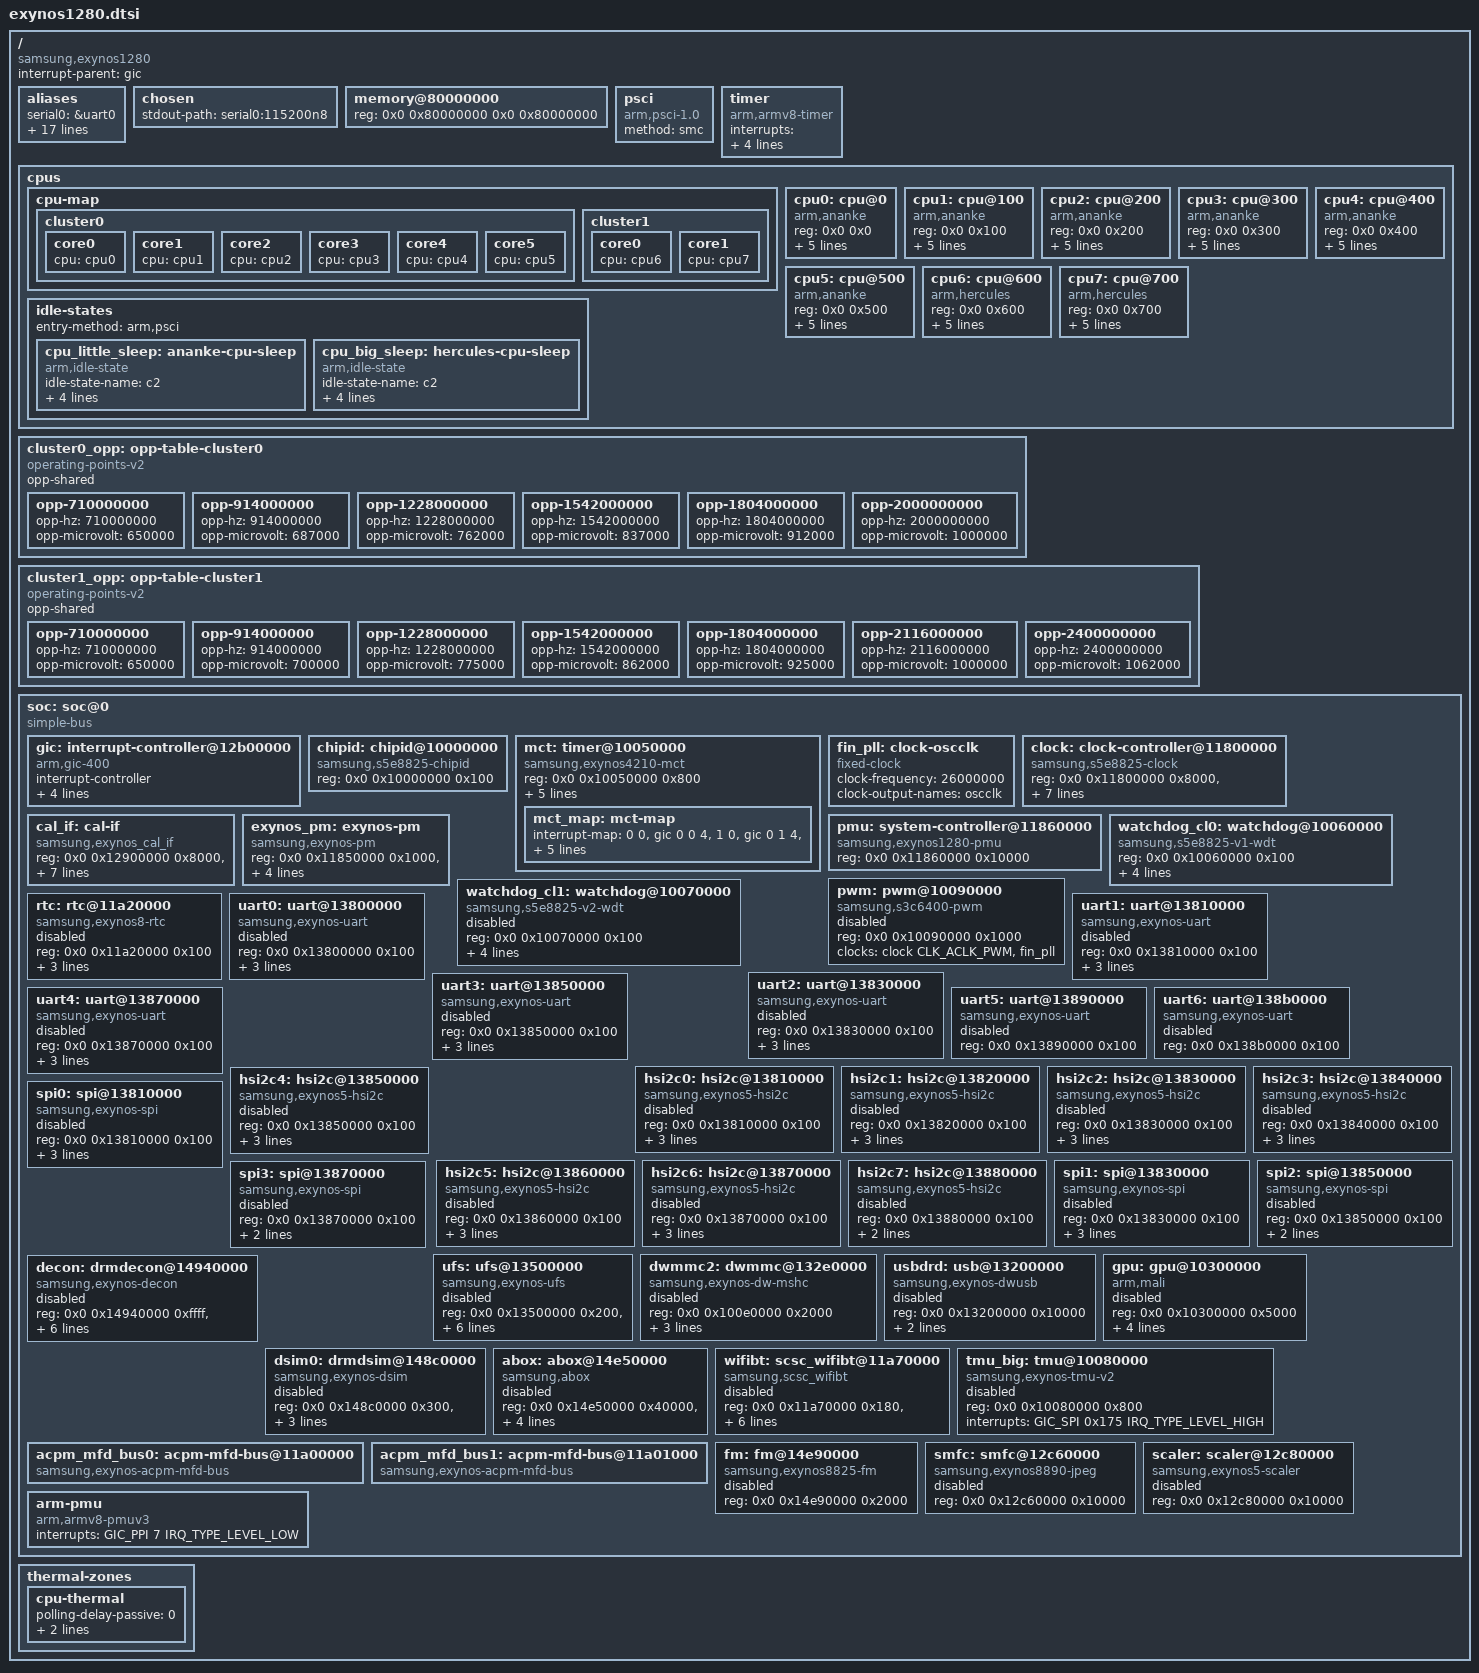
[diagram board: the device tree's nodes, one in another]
// SPDX-License-Identifier: GPL-2.0
/*
 * Samsung Exynos 1280 (s5e8825) SoC Device Tree Source
 *
 * Base addresses, IRQ numbers, and compatible strings are transcribed from
 * the device tree shipped in Samsung's official firmware
 * (A536BXXSMGZE1, SM-A536B / Galaxy A53 5G), extracted from vendor_boot.img.
 * See docs/reference-a53-real.dts for the full decoded dump.
 *
 * Key facts learned from the real DT:
 *   - Interrupt controller is arm,gic-400 (GICv2), NOT GICv3.
 *   - The clock tree is driven through ACPM IPC (acpm-ipc-channel) rather
 *     than direct register writes; the samsung,s5e8825-clock node is the
 *     ACPM front-end, and samsung,exynos_cal_if is the CAL-IF register map.
 *   - CPUs are arm,ananke (Cortex-A55, 6 cores, LITTLE) and arm,hercules
 *     (Cortex-A78, 2 cores, big). cluster0 = LITTLE, cluster1 = big.
 *   - 26 MHz oscillator (0x018cba80).
 *
 * Board-specific GPIO/regulator details remain in per-device .dts files.
 */

#include <dt-bindings/clock/samsung,exynos1280-clk.h>
#include <dt-bindings/interrupt-controller/arm-gic.h>
#include <dt-bindings/gpio/gpio.h>

/ {
	compatible = "samsung,exynos1280";
	#address-cells = <2>;
	#size-cells = <2>;

	interrupt-parent = <&gic>;

	aliases {
		serial0 = &uart0;
		serial1 = &uart1;
		serial2 = &uart2;
		serial3 = &uart3;
		serial4 = &uart4;
		serial5 = &uart5;
		serial6 = &uart6;
		mmc0 = &ufs;
		mmc2 = &dwmmc2;
		usb = &usbdrd;
		i2c0 = &hsi2c0;
		i2c1 = &hsi2c1;
		i2c2 = &hsi2c2;
		i2c3 = &hsi2c3;
		i2c4 = &hsi2c4;
		i2c5 = &hsi2c5;
		i2c6 = &hsi2c6;
		i2c7 = &hsi2c7;
	};

	chosen {
		/* UART0 (0x13800000) is the debug console on this SoC. */
		stdout-path = "serial0:115200n8";
	};

	memory@80000000 {
		device_type = "memory";
		reg = <0x0 0x80000000 0x0 0x80000000>;
	};

	psci {
		compatible = "arm,psci-1.0";
		method = "smc";
	};

	timer {
		compatible = "arm,armv8-timer";
		interrupts = <GIC_PPI 13 (GIC_CPU_MASK_SIMPLE(8) | IRQ_TYPE_LEVEL_LOW)>,
			     <GIC_PPI 14 (GIC_CPU_MASK_SIMPLE(8) | IRQ_TYPE_LEVEL_LOW)>,
			     <GIC_PPI 11 (GIC_CPU_MASK_SIMPLE(8) | IRQ_TYPE_LEVEL_LOW)>,
			     <GIC_PPI 10 (GIC_CPU_MASK_SIMPLE(8) | IRQ_TYPE_LEVEL_LOW)>;
	};

	/* â”€â”€ CPUs: 6Ã— Ananke (Cortex-A55) + 2Ã— Hercules (Cortex-A78) â”€â”€ */
	cpus {
		#address-cells = <2>;
		#size-cells = <0>;

		cpu-map {
			cluster0 {
				core0 { cpu = <&cpu0>; };
				core1 { cpu = <&cpu1>; };
				core2 { cpu = <&cpu2>; };
				core3 { cpu = <&cpu3>; };
				core4 { cpu = <&cpu4>; };
				core5 { cpu = <&cpu5>; };
			};
			cluster1 {
				core0 { cpu = <&cpu6>; };
				core1 { cpu = <&cpu7>; };
			};
		};

		/* LITTLE cluster: Cortex-A55 (Ananke) */
		cpu0: cpu@0 {
			device_type = "cpu";
			compatible = "arm,ananke", "arm,armv8";
			reg = <0x0 0x0>;
			enable-method = "psci";
			capacity-dmips-mhz = <260>;
			dynamic-power-coefficient = <89>;
			operating-points-v2 = <&cluster0_opp>;
			cpu-idle-states = <&cpu_little_sleep>;
			#cooling-cells = <2>;
		};

		cpu1: cpu@100 {
			device_type = "cpu";
			compatible = "arm,ananke", "arm,armv8";
			reg = <0x0 0x100>;
			enable-method = "psci";
			capacity-dmips-mhz = <260>;
			dynamic-power-coefficient = <89>;
			operating-points-v2 = <&cluster0_opp>;
			cpu-idle-states = <&cpu_little_sleep>;
			#cooling-cells = <2>;
		};

		cpu2: cpu@200 {
			device_type = "cpu";
			compatible = "arm,ananke", "arm,armv8";
			reg = <0x0 0x200>;
			enable-method = "psci";
			capacity-dmips-mhz = <260>;
			dynamic-power-coefficient = <89>;
			operating-points-v2 = <&cluster0_opp>;
			cpu-idle-states = <&cpu_little_sleep>;
			#cooling-cells = <2>;
		};

		cpu3: cpu@300 {
			device_type = "cpu";
			compatible = "arm,ananke", "arm,armv8";
			reg = <0x0 0x300>;
			enable-method = "psci";
			capacity-dmips-mhz = <260>;
			dynamic-power-coefficient = <89>;
			operating-points-v2 = <&cluster0_opp>;
			cpu-idle-states = <&cpu_little_sleep>;
			#cooling-cells = <2>;
		};

		cpu4: cpu@400 {
			device_type = "cpu";
			compatible = "arm,ananke", "arm,armv8";
			reg = <0x0 0x400>;
			enable-method = "psci";
			capacity-dmips-mhz = <260>;
			dynamic-power-coefficient = <89>;
			operating-points-v2 = <&cluster0_opp>;
			cpu-idle-states = <&cpu_little_sleep>;
			#cooling-cells = <2>;
		};

		cpu5: cpu@500 {
			device_type = "cpu";
			compatible = "arm,ananke", "arm,armv8";
			reg = <0x0 0x500>;
			enable-method = "psci";
			capacity-dmips-mhz = <260>;
			dynamic-power-coefficient = <89>;
			operating-points-v2 = <&cluster0_opp>;
			cpu-idle-states = <&cpu_little_sleep>;
			#cooling-cells = <2>;
		};

		/* Big cluster: Cortex-A78 (Hercules) */
		cpu6: cpu@600 {
			device_type = "cpu";
			compatible = "arm,hercules", "arm,armv8";
			reg = <0x0 0x600>;
			enable-method = "psci";
			capacity-dmips-mhz = <880>;
			dynamic-power-coefficient = <513>;
			operating-points-v2 = <&cluster1_opp>;
			cpu-idle-states = <&cpu_big_sleep>;
			#cooling-cells = <2>;
		};

		cpu7: cpu@700 {
			device_type = "cpu";
			compatible = "arm,hercules", "arm,armv8";
			reg = <0x0 0x700>;
			enable-method = "psci";
			capacity-dmips-mhz = <880>;
			dynamic-power-coefficient = <513>;
			operating-points-v2 = <&cluster1_opp>;
			cpu-idle-states = <&cpu_big_sleep>;
			#cooling-cells = <2>;
		};

		idle-states {
			entry-method = "arm,psci";

			cpu_little_sleep: ananke-cpu-sleep {
				idle-state-name = "c2";
				compatible = "arm,idle-state";
				arm,psci-suspend-param = <0x00010000>;
				entry-latency-us = <70>;
				exit-latency-us = <160>;
				min-residency-us = <2000>;
			};

			cpu_big_sleep: hercules-cpu-sleep {
				idle-state-name = "c2";
				compatible = "arm,idle-state";
				arm,psci-suspend-param = <0x00010000>;
				entry-latency-us = <150>;
				exit-latency-us = <190>;
				min-residency-us = <2500>;
			};
		};
	};

	/* LITTLE cluster (Cortex-A55) OPP table */
	cluster0_opp: opp-table-cluster0 {
		compatible = "operating-points-v2";
		opp-shared;

		opp-710000000 {
			opp-hz = /bits/ 64 <710000000>;
			opp-microvolt = <650000>;
		};
		opp-914000000 {
			opp-hz = /bits/ 64 <914000000>;
			opp-microvolt = <687000>;
		};
		opp-1228000000 {
			opp-hz = /bits/ 64 <1228000000>;
			opp-microvolt = <762000>;
		};
		opp-1542000000 {
			opp-hz = /bits/ 64 <1542000000>;
			opp-microvolt = <837000>;
		};
		opp-1804000000 {
			opp-hz = /bits/ 64 <1804000000>;
			opp-microvolt = <912000>;
		};
		opp-2000000000 {
			opp-hz = /bits/ 64 <2000000000>;
			opp-microvolt = <1000000>;
		};
	};

	/* Big cluster (Cortex-A78) OPP table */
	cluster1_opp: opp-table-cluster1 {
		compatible = "operating-points-v2";
		opp-shared;

		opp-710000000 {
			opp-hz = /bits/ 64 <710000000>;
			opp-microvolt = <650000>;
		};
		opp-914000000 {
			opp-hz = /bits/ 64 <914000000>;
			opp-microvolt = <700000>;
		};
		opp-1228000000 {
			opp-hz = /bits/ 64 <1228000000>;
			opp-microvolt = <775000>;
		};
		opp-1542000000 {
			opp-hz = /bits/ 64 <1542000000>;
			opp-microvolt = <862000>;
		};
		opp-1804000000 {
			opp-hz = /bits/ 64 <1804000000>;
			opp-microvolt = <925000>;
		};
		opp-2116000000 {
			opp-hz = /bits/ 64 <2116000000>;
			opp-microvolt = <1000000>;
		};
		opp-2400000000 {
			opp-hz = /bits/ 64 <2400000000>;
			opp-microvolt = <1062000>;
		};
	};

	/* â”€â”€ SoC bus â”€â”€â”€â”€â”€â”€â”€â”€â”€â”€â”€â”€â”€â”€â”€â”€â”€â”€â”€â”€â”€â”€â”€â”€â”€â”€â”€â”€â”€â”€â”€â”€â”€â”€â”€â”€â”€â”€â”€â”€â”€â”€â”€â”€â”€â”€â”€â”€â”€â”€â”€â”€â”€â”€â”€ */

	soc: soc@0 {
		compatible = "simple-bus";
		#address-cells = <2>;
		#size-cells = <1>;
		ranges = <0x0 0x00000000 0x0 0x00000000 0x00000000
		          0x0 0x80000000 0x0 0x80000000 0x80000000>;

		/* â”€â”€ GIC-400 (GICv2) â”€â”€â”€â”€â”€â”€â”€â”€â”€â”€â”€â”€â”€â”€â”€â”€â”€â”€â”€â”€â”€â”€â”€â”€â”€â”€â”€â”€â”€â”€â”€â”€â”€â”€â”€â”€â”€â”€â”€â”€ */
		/* NOT GICv3: this SoC uses arm,gic-400 with the GICv2 ABI. */
		gic: interrupt-controller@12b00000 {
			compatible = "arm,gic-400";
			#interrupt-cells = <3>;
			#address-cells = <0>;
			interrupt-controller;
			reg = <0x0 0x12b01000 0x1000>,   /* GICD */
			      <0x0 0x12b02000 0x1000>,   /* GICC */
			      <0x0 0x12b04000 0x2000>,   /* GICH */
			      <0x0 0x12b06000 0x2000>;   /* GICV */
			interrupts = <GIC_PPI 9 0xf04>;  /* maintenance */
		};

		/* â”€â”€ ChipID â”€â”€â”€â”€â”€â”€â”€â”€â”€â”€â”€â”€â”€â”€â”€â”€â”€â”€â”€â”€â”€â”€â”€â”€â”€â”€â”€â”€â”€â”€â”€â”€â”€â”€â”€â”€â”€â”€â”€â”€â”€â”€â”€â”€â”€â”€â”€â”€ */
		chipid: chipid@10000000 {
			compatible = "samsung,s5e8825-chipid";
			reg = <0x0 0x10000000 0x100>;
		};

		/* â”€â”€ Multi-Core Timer (sched_clock source) â”€â”€â”€â”€â”€â”€â”€â”€â”€â”€â”€â”€â”€â”€â”€â”€ */
		mct: timer@10050000 {
			compatible = "samsung,exynos4210-mct";
			reg = <0x0 0x10050000 0x800>;
			interrupt-controller;
			#interrupt-cells = <1>;
			interrupt-parent = <&mct_map>;
			interrupts = <0>, <1>, <2>, <3>, <4>, <5>, <6>, <7>,
				     <8>, <9>, <10>, <11>;
			clocks = <&fin_pll>, <&fin_pll>;
			clock-names = "fin_pll", "mct";

			mct_map: mct-map {
				#interrupt-cells = <1>;
				#address-cells = <0>;
				#size-cells = <0>;
				interrupt-map = <0 0 &gic 0 0 4>,
						<1 0 &gic 0 1 4>,
						<2 0 &gic 0 2 4>,
						<3 0 &gic 0 3 4>,
						<4 0 &gic 0 4 4>,
						<5 0 &gic 0 5 4>,
						<6 0 &gic 0 6 4>,
						<7 0 &gic 0 7 4>,
						<8 0 &gic 0 8 4>,
						<9 0 &gic 0 9 4>,
						<10 0 &gic 0 10 4>,
						<11 0 &gic 0 11 4>;
			};
		};

		/* â”€â”€ Oscillator (26 MHz) â”€â”€â”€â”€â”€â”€â”€â”€â”€â”€â”€â”€â”€â”€â”€â”€â”€â”€â”€â”€â”€â”€â”€â”€â”€â”€â”€â”€â”€â”€â”€â”€â”€â”€â”€ */
		fin_pll: clock-oscclk {
			compatible = "fixed-clock";
			#clock-cells = <0>;
			clock-frequency = <26000000>;
			clock-output-names = "oscclk";
		};

		/* â”€â”€ Clock controller (ACPM front-end) â”€â”€â”€â”€â”€â”€â”€â”€â”€â”€â”€â”€â”€â”€â”€â”€â”€â”€â”€â”€â”€ */
		/* Samsung drives the clock tree through ACPM IPC; this node
		 * is the mailbox front-end. The real register map is cal_if. */
		clock: clock-controller@11800000 {
			compatible = "samsung,s5e8825-clock";
			reg = <0x0 0x11800000 0x8000>,   /* CMU_TOP (8 KB) */
			      <0x0 0x18c00000 0x1000>,   /* ACPM SFR */
			      <0x0 0x1a030000 0x1000>,
			      <0x0 0x1d040000 0x1000>,
			      <0x0 0x1d050000 0x1000>,
			      <0x0 0x1d060000 0x1000>,
			      <0x0 0x1d030000 0x1000>,
			      <0x0 0x10020000 0x1000>;   /* SYSREG */
			#clock-cells = <1>;
			acpm-ipc-channel = <0>;
		};

		/* â”€â”€ CAL-IF register map â”€â”€â”€â”€â”€â”€â”€â”€â”€â”€â”€â”€â”€â”€â”€â”€â”€â”€â”€â”€â”€â”€â”€â”€â”€â”€â”€â”€â”€â”€â”€â”€â”€â”€â”€ */
		cal_if: cal-if {
			compatible = "samsung,exynos_cal_if";
			reg = <0x0 0x12900000 0x8000>,   /* CMU_TOP mirror */
			      <0x0 0x14e00000 0x1000>,   /* CMU_AUD */
			      <0x0 0x1a030000 0x1000>,
			      <0x0 0x10820000 0x1000>,   /* CMU_CPUCL0 */
			      <0x0 0x10830000 0x1000>,   /* CMU_CPUCL1 */
			      <0x0 0x1d060000 0x1000>,
			      <0x0 0x108a0000 0x1000>,
			      <0x0 0x10030000 0x1000>;   /* CMU_PERI */
			acpm-ipc-channel = <0>;
		};

		/* â”€â”€ PMU / System controller â”€â”€â”€â”€â”€â”€â”€â”€â”€â”€â”€â”€â”€â”€â”€â”€â”€â”€â”€â”€â”€â”€â”€â”€â”€â”€â”€â”€â”€â”€ */
		pmu: system-controller@11860000 {
			compatible = "samsung,exynos1280-pmu", "syscon";
			reg = <0x0 0x11860000 0x10000>;
		};

		exynos_pm: exynos-pm {
			compatible = "samsung,exynos-pm";
			reg = <0x0 0x11850000 0x1000>,   /* gpio_alive_base */
			      <0x0 0x12b01200 0x100>,    /* gicd_ispendrn_base */
			      <0x0 0x11a60000 0x1000>;   /* sysreg_vgpio2pmu */
			reg-names = "gpio_alive_base",
				    "gicd_ispendrn_base",
				    "sysreg_vgpio2pmu";
			num-eint = <12>;
			num-gic = <16>;
			samsung,syscon-phandle = <&pmu>;
		};

		/* â”€â”€ Watchdogs â”€â”€â”€â”€â”€â”€â”€â”€â”€â”€â”€â”€â”€â”€â”€â”€â”€â”€â”€â”€â”€â”€â”€â”€â”€â”€â”€â”€â”€â”€â”€â”€â”€â”€â”€â”€â”€â”€â”€â”€â”€â”€â”€â”€â”€ */
		watchdog_cl0: watchdog@10060000 {
			compatible = "samsung,s5e8825-v1-wdt";
			reg = <0x0 0x10060000 0x100>;
			interrupts = <GIC_SPI 0x186 IRQ_TYPE_LEVEL_HIGH>;
			clocks = <&fin_pll>, <&clock CLK_PCLK_WDT>;
			clock-names = "rate_watchdog", "gate_watchdog";
			timeout-sec = <80>;
			samsung,syscon-phandle = <&pmu>;
			status = "okay";
		};

		watchdog_cl1: watchdog@10070000 {
			compatible = "samsung,s5e8825-v2-wdt";
			reg = <0x0 0x10070000 0x100>;
			interrupts = <GIC_SPI 0x187 IRQ_TYPE_LEVEL_HIGH>;
			clocks = <&fin_pll>, <&clock CLK_PCLK_WDT>;
			clock-names = "rate_watchdog", "gate_watchdog";
			timeout-sec = <80>;
			samsung,syscon-phandle = <&pmu>;
			status = "disabled";
		};

		/* â”€â”€ PWM â”€â”€â”€â”€â”€â”€â”€â”€â”€â”€â”€â”€â”€â”€â”€â”€â”€â”€â”€â”€â”€â”€â”€â”€â”€â”€â”€â”€â”€â”€â”€â”€â”€â”€â”€â”€â”€â”€â”€â”€â”€â”€â”€â”€â”€â”€â”€â”€â”€â”€â”€ */
		pwm: pwm@10090000 {
			compatible = "samsung,s3c6400-pwm";
			reg = <0x0 0x10090000 0x1000>;
			clocks = <&clock CLK_ACLK_PWM>, <&fin_pll>;
			clock-names = "pwm_pclk", "pwm_sclk";
			#pwm-cells = <3>;
			status = "disabled";
		};

		/* â”€â”€ RTC â”€â”€â”€â”€â”€â”€â”€â”€â”€â”€â”€â”€â”€â”€â”€â”€â”€â”€â”€â”€â”€â”€â”€â”€â”€â”€â”€â”€â”€â”€â”€â”€â”€â”€â”€â”€â”€â”€â”€â”€â”€â”€â”€â”€â”€â”€â”€â”€â”€â”€ */
		rtc: rtc@11a20000 {
			compatible = "samsung,exynos8-rtc";
			reg = <0x0 0x11a20000 0x100>;
			interrupts = <GIC_SPI 0x2a IRQ_TYPE_LEVEL_HIGH>,
				     <GIC_SPI 0x2b IRQ_TYPE_LEVEL_HIGH>;
			clocks = <&fin_pll>;
			clock-names = "rtc";
			status = "disabled";
		};

		/* â”€â”€ UART (debug console is uart0 @ 0x13800000) â”€â”€â”€â”€â”€â”€â”€â”€â”€â”€â”€ */
		uart0: uart@13800000 {
			compatible = "samsung,exynos-uart";
			reg = <0x0 0x13800000 0x100>;
			interrupts = <GIC_SPI 0x176 IRQ_TYPE_LEVEL_HIGH>;
			clocks = <&clock CLK_SCLK_UART0>,
				 <&clock CLK_PCLK_UART0>;
			clock-names = "gate_uart_clk0", "ipclk_uart0";
			status = "disabled";
		};

		uart1: uart@13810000 {
			compatible = "samsung,exynos-uart";
			reg = <0x0 0x13810000 0x100>;
			interrupts = <GIC_SPI 0x178 IRQ_TYPE_LEVEL_HIGH>;
			clocks = <&clock CLK_SCLK_UART1>,
				 <&clock CLK_PCLK_UART1>;
			clock-names = "gate_uart_clk0", "ipclk_uart0";
			status = "disabled";
		};

		uart2: uart@13830000 {
			compatible = "samsung,exynos-uart";
			reg = <0x0 0x13830000 0x100>;
			interrupts = <GIC_SPI 0x17a IRQ_TYPE_LEVEL_HIGH>;
			clocks = <&clock CLK_SCLK_UART2>,
				 <&clock CLK_PCLK_UART2>;
			clock-names = "gate_uart_clk0", "ipclk_uart0";
			status = "disabled";
		};

		uart3: uart@13850000 {
			compatible = "samsung,exynos-uart";
			reg = <0x0 0x13850000 0x100>;
			interrupts = <GIC_SPI 0x17c IRQ_TYPE_LEVEL_HIGH>;
			clocks = <&clock CLK_SCLK_UART3>,
				 <&clock CLK_PCLK_UART3>;
			clock-names = "gate_uart_clk0", "ipclk_uart0";
			status = "disabled";
		};

		uart4: uart@13870000 {
			compatible = "samsung,exynos-uart";
			reg = <0x0 0x13870000 0x100>;
			interrupts = <GIC_SPI 0x17e IRQ_TYPE_LEVEL_HIGH>;
			clocks = <&clock CLK_SCLK_UART4>,
				 <&clock CLK_PCLK_UART4>;
			clock-names = "gate_uart_clk0", "ipclk_uart0";
			status = "disabled";
		};

		uart5: uart@13890000 {
			compatible = "samsung,exynos-uart";
			reg = <0x0 0x13890000 0x100>;
			status = "disabled";
		};

		uart6: uart@138b0000 {
			compatible = "samsung,exynos-uart";
			reg = <0x0 0x138b0000 0x100>;
			status = "disabled";
		};

		/* â”€â”€ I2C (HSI2C) â€” USI blocks shared with SPI â”€â”€â”€â”€â”€â”€â”€â”€â”€â”€â”€â”€â”€ */
		hsi2c0: hsi2c@13810000 {
			compatible = "samsung,exynos5-hsi2c";
			reg = <0x0 0x13810000 0x100>;
			interrupts = <GIC_SPI 0x178 IRQ_TYPE_LEVEL_HIGH>;
			clocks = <&clock CLK_PCLK_I2C0>, <&clock CLK_PCLK_I2C0>;
			clock-names = "ipclk_hsi2c", "gate_hsi2c_clk";
			#address-cells = <1>;
			#size-cells = <0>;
			status = "disabled";
		};

		hsi2c1: hsi2c@13820000 {
			compatible = "samsung,exynos5-hsi2c";
			reg = <0x0 0x13820000 0x100>;
			interrupts = <GIC_SPI 0x177 IRQ_TYPE_LEVEL_HIGH>;
			clocks = <&clock CLK_PCLK_I2C1>, <&clock CLK_PCLK_I2C1>;
			clock-names = "ipclk_hsi2c", "gate_hsi2c_clk";
			#address-cells = <1>;
			#size-cells = <0>;
			status = "disabled";
		};

		hsi2c2: hsi2c@13830000 {
			compatible = "samsung,exynos5-hsi2c";
			reg = <0x0 0x13830000 0x100>;
			interrupts = <GIC_SPI 0x17a IRQ_TYPE_LEVEL_HIGH>;
			clocks = <&clock CLK_PCLK_I2C2>, <&clock CLK_PCLK_I2C2>;
			clock-names = "ipclk_hsi2c", "gate_hsi2c_clk";
			#address-cells = <1>;
			#size-cells = <0>;
			status = "disabled";
		};

		hsi2c3: hsi2c@13840000 {
			compatible = "samsung,exynos5-hsi2c";
			reg = <0x0 0x13840000 0x100>;
			interrupts = <GIC_SPI 0x179 IRQ_TYPE_LEVEL_HIGH>;
			clocks = <&clock CLK_PCLK_I2C3>, <&clock CLK_PCLK_I2C3>;
			clock-names = "ipclk_hsi2c", "gate_hsi2c_clk";
			#address-cells = <1>;
			#size-cells = <0>;
			status = "disabled";
		};

		hsi2c4: hsi2c@13850000 {
			compatible = "samsung,exynos5-hsi2c";
			reg = <0x0 0x13850000 0x100>;
			interrupts = <GIC_SPI 0x17c IRQ_TYPE_LEVEL_HIGH>;
			clocks = <&clock CLK_PCLK_I2C4>, <&clock CLK_PCLK_I2C4>;
			clock-names = "ipclk_hsi2c", "gate_hsi2c_clk";
			#address-cells = <1>;
			#size-cells = <0>;
			status = "disabled";
		};

		hsi2c5: hsi2c@13860000 {
			compatible = "samsung,exynos5-hsi2c";
			reg = <0x0 0x13860000 0x100>;
			interrupts = <GIC_SPI 0x17b IRQ_TYPE_LEVEL_HIGH>;
			clocks = <&clock CLK_PCLK_I2C5>, <&clock CLK_PCLK_I2C5>;
			clock-names = "ipclk_hsi2c", "gate_hsi2c_clk";
			#address-cells = <1>;
			#size-cells = <0>;
			status = "disabled";
		};

		hsi2c6: hsi2c@13870000 {
			compatible = "samsung,exynos5-hsi2c";
			reg = <0x0 0x13870000 0x100>;
			interrupts = <GIC_SPI 0x17e IRQ_TYPE_LEVEL_HIGH>;
			clocks = <&clock CLK_PCLK_I2C6>, <&clock CLK_PCLK_I2C6>;
			clock-names = "ipclk_hsi2c", "gate_hsi2c_clk";
			#address-cells = <1>;
			#size-cells = <0>;
			status = "disabled";
		};

		hsi2c7: hsi2c@13880000 {
			compatible = "samsung,exynos5-hsi2c";
			reg = <0x0 0x13880000 0x100>;
			clocks = <&clock CLK_PCLK_I2C7>, <&clock CLK_PCLK_I2C7>;
			clock-names = "ipclk_hsi2c", "gate_hsi2c_clk";
			#address-cells = <1>;
			#size-cells = <0>;
			status = "disabled";
		};

		/* â”€â”€ SPI (shares USI blocks with UART/I2C) â”€â”€â”€â”€â”€â”€â”€â”€â”€â”€â”€â”€â”€â”€â”€â”€ */
		spi0: spi@13810000 {
			compatible = "samsung,exynos-spi";
			reg = <0x0 0x13810000 0x100>;
			interrupts = <GIC_SPI 0x178 IRQ_TYPE_LEVEL_HIGH>;
			clocks = <&clock CLK_PCLK_SPI0>, <&clock CLK_PCLK_SPI0>;
			clock-names = "spi", "spi_busclk0";
			#address-cells = <1>;
			#size-cells = <0>;
			status = "disabled";
		};

		spi1: spi@13830000 {
			compatible = "samsung,exynos-spi";
			reg = <0x0 0x13830000 0x100>;
			interrupts = <GIC_SPI 0x17a IRQ_TYPE_LEVEL_HIGH>;
			clocks = <&clock CLK_PCLK_SPI1>, <&clock CLK_PCLK_SPI1>;
			clock-names = "spi", "spi_busclk0";
			#address-cells = <1>;
			#size-cells = <0>;
			status = "disabled";
		};

		spi2: spi@13850000 {
			compatible = "samsung,exynos-spi";
			reg = <0x0 0x13850000 0x100>;
			clocks = <&clock CLK_PCLK_SPI2>, <&clock CLK_PCLK_SPI2>;
			clock-names = "spi", "spi_busclk0";
			#address-cells = <1>;
			#size-cells = <0>;
			status = "disabled";
		};

		spi3: spi@13870000 {
			compatible = "samsung,exynos-spi";
			reg = <0x0 0x13870000 0x100>;
			clocks = <&clock CLK_PCLK_SPI3>, <&clock CLK_PCLK_SPI3>;
			clock-names = "spi", "spi_busclk0";
			#address-cells = <1>;
			#size-cells = <0>;
			status = "disabled";
		};

		/* â”€â”€ UFS (internal storage) â”€â”€â”€â”€â”€â”€â”€â”€â”€â”€â”€â”€â”€â”€â”€â”€â”€â”€â”€â”€â”€â”€â”€â”€â”€â”€â”€â”€â”€â”€â”€â”€ */
		ufs: ufs@13500000 {
			compatible = "samsung,exynos-ufs";
			#address-cells = <2>;
			#size-cells = <1>;
			ranges;
			reg = <0x0 0x13500000 0x200>,     /* HCI */
			      <0x0 0x13501100 0x2000>,    /* UNIPRO */
			      <0x0 0x13580000 0x8000>,    /* UFS PHY */
			      <0x0 0x135a0000 0xa014>,    /* PHY PMA */
			      <0x0 0x13504000 0x4000>,    /* UNIPRO stall */
			      <0x0 0x13508000 0x804>;     /* PMU */
			interrupts = <GIC_SPI 0x113 IRQ_TYPE_LEVEL_HIGH>;
			clocks = <&clock CLK_ACLK_UFS>,
				 <&clock CLK_SCLK_UFS>;
			clock-names = "GATE_UFS_EMBD", "UFS_EMBD";
			status = "disabled";
		};

		/* â”€â”€ eMMC / SD (DWMMC2) â”€â”€â”€â”€â”€â”€â”€â”€â”€â”€â”€â”€â”€â”€â”€â”€â”€â”€â”€â”€â”€â”€â”€â”€â”€â”€â”€â”€â”€â”€â”€â”€â”€â”€â”€â”€ */
		dwmmc2: dwmmc@132e0000 {
			compatible = "samsung,exynos-dw-mshc";
			reg = <0x0 0x100e0000 0x2000>;
			reg-names = "dw_mmc";
			interrupts = <GIC_SPI 0x16c IRQ_TYPE_LEVEL_HIGH>;
			clocks = <&clock CLK_SCLK_MMC2>,
				 <&clock CLK_PCLK_MMC2>;
			clock-names = "ciu", "ciu_gate";
			#address-cells = <1>;
			#size-cells = <0>;
			status = "disabled";
		};

		/* â”€â”€ USB 3.0 (DWC3) â”€â”€â”€â”€â”€â”€â”€â”€â”€â”€â”€â”€â”€â”€â”€â”€â”€â”€â”€â”€â”€â”€â”€â”€â”€â”€â”€â”€â”€â”€â”€â”€â”€â”€â”€â”€â”€â”€â”€â”€ */
		usbdrd: usb@13200000 {
			compatible = "samsung,exynos-dwusb";
			reg = <0x0 0x13200000 0x10000>;
			interrupts = <GIC_SPI 0x1a2 IRQ_TYPE_LEVEL_HIGH>;
			clocks = <&clock CLK_ACLK_USB>,
				 <&clock CLK_SCLK_USB>;
			clock-names = "aclk", "sclk";
			#address-cells = <2>;
			#size-cells = <1>;
			ranges;
			status = "disabled";
		};

		/* â”€â”€ Mali GPU â”€â”€â”€â”€â”€â”€â”€â”€â”€â”€â”€â”€â”€â”€â”€â”€â”€â”€â”€â”€â”€â”€â”€â”€â”€â”€â”€â”€â”€â”€â”€â”€â”€â”€â”€â”€â”€â”€â”€â”€â”€â”€â”€â”€â”€â”€â”€ */
		gpu: gpu@10300000 {
			compatible = "arm,mali";
			reg = <0x0 0x10300000 0x5000>;
			interrupts = <GIC_SPI 0x107 IRQ_TYPE_LEVEL_HIGH>,
				     <GIC_SPI 0x108 IRQ_TYPE_LEVEL_HIGH>,
				     <GIC_SPI 0x106 IRQ_TYPE_LEVEL_HIGH>;
			interrupt-names = "JOB", "MMU", "GPU";
			clocks = <&clock CLK_ACLK_GPU>;
			clock-names = "gpu_clock";
			status = "disabled";
		};

		/* â”€â”€ Display (DECON + DSIM) â”€â”€â”€â”€â”€â”€â”€â”€â”€â”€â”€â”€â”€â”€â”€â”€â”€â”€â”€â”€â”€â”€â”€â”€â”€â”€â”€â”€â”€â”€â”€â”€ */
		decon: drmdecon@14940000 {
			compatible = "samsung,exynos-decon";
			reg = <0x0 0x14940000 0xffff>,   /* main */
			      <0x0 0x14950000 0xffff>,   /* win */
			      <0x0 0x14960000 0xffff>,   /* sub */
			      <0x0 0x14970000 0xffff>,   /* wincon */
			      <0x0 0x149b0000 0xffff>;   /* dqe */
			reg-names = "main", "win", "sub", "wincon", "dqe";
			interrupts = <GIC_SPI 0xe3 IRQ_TYPE_LEVEL_HIGH>,
				     <GIC_SPI 0xe2 IRQ_TYPE_LEVEL_HIGH>,
				     <GIC_SPI 0xdd IRQ_TYPE_LEVEL_HIGH>;
			interrupt-names = "frame_start", "frame_done", "extra";
			status = "disabled";
		};

		dsim0: drmdsim@148c0000 {
			compatible = "samsung,exynos-dsim";
			reg = <0x0 0x148c0000 0x300>,     /* dsi */
			      <0x0 0x148e0100 0x700>,     /* dphy */
			      <0x0 0x148e0000 0x100>,     /* dphy-extra */
			      <0x0 0x12cd0000 0x10000>;   /* votf */
			reg-names = "dsi", "dphy", "dphy-extra", "votf";
			interrupts = <GIC_SPI 0xfc IRQ_TYPE_LEVEL_HIGH>;
			interrupt-names = "dsim";
			#address-cells = <1>;
			#size-cells = <0>;
			status = "disabled";
		};

		/* â”€â”€ Audio (ABOX) â”€â”€â”€â”€â”€â”€â”€â”€â”€â”€â”€â”€â”€â”€â”€â”€â”€â”€â”€â”€â”€â”€â”€â”€â”€â”€â”€â”€â”€â”€â”€â”€â”€â”€â”€â”€â”€â”€â”€â”€â”€â”€ */
		abox: abox@14e50000 {
			compatible = "samsung,abox";
			reg = <0x0 0x14e50000 0x40000>,   /* sfr */
			      <0x0 0x14e10000 0x10000>,   /* sysreg */
			      <0x0 0x14f00000 0x85000>,   /* sram */
			      <0x0 0x14ee0000 0x10000>,   /* timer */
			      <0x0 0x119c0000 0x1000>;    /* mailbox_apm */
			reg-names = "sfr", "sysreg", "sram", "timer", "mailbox_apm";
			status = "disabled";
		};

		/* â”€â”€ WiFi/BT (SCSC) â”€â”€â”€â”€â”€â”€â”€â”€â”€â”€â”€â”€â”€â”€â”€â”€â”€â”€â”€â”€â”€â”€â”€â”€â”€â”€â”€â”€â”€â”€â”€â”€â”€â”€â”€â”€â”€â”€â”€â”€ */
		wifibt: scsc_wifibt@11a70000 {
			compatible = "samsung,scsc_wifibt";
			reg = <0x0 0x11a70000 0x180>,
			      <0x0 0x11a80000 0x180>,
			      <0x0 0x119b0000 0x180>;
			interrupts = <GIC_SPI 0x17 IRQ_TYPE_LEVEL_HIGH>,
				     <GIC_SPI 0x28 IRQ_TYPE_LEVEL_HIGH>,
				     <GIC_SPI 0x27 IRQ_TYPE_LEVEL_HIGH>,
				     <GIC_SPI 0x1a6 IRQ_TYPE_LEVEL_HIGH>,
				     <GIC_SPI 0x1a7 IRQ_TYPE_LEVEL_HIGH>;
			interrupt-names = "ALIVE", "MBOX_WLAN", "MBOX_WPAN",
					  "CFG_REQ", "WDOG";
			status = "disabled";
		};

		/* â”€â”€ Thermal (TMU) â”€â”€â”€â”€â”€â”€â”€â”€â”€â”€â”€â”€â”€â”€â”€â”€â”€â”€â”€â”€â”€â”€â”€â”€â”€â”€â”€â”€â”€â”€â”€â”€â”€â”€â”€â”€â”€â”€â”€â”€â”€ */
		tmu_big: tmu@10080000 {
			compatible = "samsung,exynos-tmu-v2";
			reg = <0x0 0x10080000 0x800>;
			interrupts = <GIC_SPI 0x175 IRQ_TYPE_LEVEL_HIGH>;
			#thermal-sensor-cells = <0>;
			status = "disabled";
		};

		/* â”€â”€ ACPM MFD bus â”€â”€â”€â”€â”€â”€â”€â”€â”€â”€â”€â”€â”€â”€â”€â”€â”€â”€â”€â”€â”€â”€â”€â”€â”€â”€â”€â”€â”€â”€â”€â”€â”€â”€â”€â”€â”€â”€â”€â”€â”€ */
		acpm_mfd_bus0: acpm-mfd-bus@11a00000 {
			compatible = "samsung,exynos-acpm-mfd-bus";
			status = "okay";
		};

		acpm_mfd_bus1: acpm-mfd-bus@11a01000 {
			compatible = "samsung,exynos-acpm-mfd-bus";
			status = "okay";
		};

		/* â”€â”€ FM radio â”€â”€â”€â”€â”€â”€â”€â”€â”€â”€â”€â”€â”€â”€â”€â”€â”€â”€â”€â”€â”€â”€â”€â”€â”€â”€â”€â”€â”€â”€â”€â”€â”€â”€â”€â”€â”€â”€â”€â”€â”€â”€â”€â”€â”€ */
		fm: fm@14e90000 {
			compatible = "samsung,exynos8825-fm";
			reg = <0x0 0x14e90000 0x2000>;
			status = "disabled";
		};

		/* â”€â”€ JPEG / MFC â”€â”€â”€â”€â”€â”€â”€â”€â”€â”€â”€â”€â”€â”€â”€â”€â”€â”€â”€â”€â”€â”€â”€â”€â”€â”€â”€â”€â”€â”€â”€â”€â”€â”€â”€â”€â”€â”€â”€â”€â”€â”€â”€ */
		smfc: smfc@12c60000 {
			compatible = "samsung,exynos8890-jpeg";
			reg = <0x0 0x12c60000 0x10000>;
			status = "disabled";
		};

		scaler: scaler@12c80000 {
			compatible = "samsung,exynos5-scaler";
			reg = <0x0 0x12c80000 0x10000>;
			status = "disabled";
		};

		/* â”€â”€ arm-pmu â”€â”€â”€â”€â”€â”€â”€â”€â”€â”€â”€â”€â”€â”€â”€â”€â”€â”€â”€â”€â”€â”€â”€â”€â”€â”€â”€â”€â”€â”€â”€â”€â”€â”€â”€â”€â”€â”€â”€â”€â”€â”€â”€â”€â”€â”€ */
		arm-pmu {
			compatible = "arm,armv8-pmuv3";
			interrupts = <GIC_PPI 7 IRQ_TYPE_LEVEL_LOW>;
		};
	}; /* soc */

	/* â”€â”€ Thermal zones â”€â”€â”€â”€â”€â”€â”€â”€â”€â”€â”€â”€â”€â”€â”€â”€â”€â”€â”€â”€â”€â”€â”€â”€â”€â”€â”€â”€â”€â”€â”€â”€â”€â”€â”€â”€â”€â”€â”€â”€â”€â”€â”€â”€ */
	thermal-zones {
		cpu-thermal {
			polling-delay-passive = <0>;
			polling-delay = <0>;
			thermal-sensors = <&tmu_big>;
		};
	};
};
